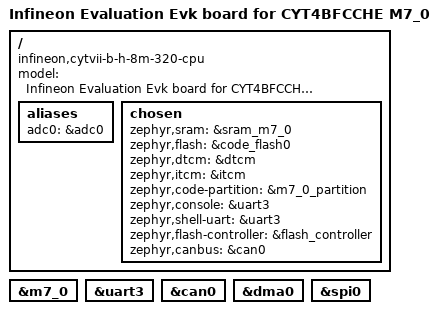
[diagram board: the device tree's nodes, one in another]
/*
 * Copyright (c) 2025 Infineon Technologies AG,
 * or an affiliate of Infineon Technologies AG.
 *
 * SPDX-License-Identifier: Apache-2.0
 */

/dts-v1/;
#include <arm/infineon/cat1c/traveo2-8m/cyt4bfcche.dtsi>
#include <arm/infineon/cat1c/traveo2-8m/system_clocks.dtsi>
#include <arm/infineon/cat1c/traveo2-8m/cyt4bf_m7.dtsi>
#include "cytvii_b_h_8m_320_cpu_common.dtsi"
#include "cytvii_b_h_8m_320_cpu_cyt4bfcche_m0p_pinctrl.dtsi"
#include <common/freq.h>

/ {
	model = "Infineon Evaluation Evk board for CYT4BFCCHE M7_0";
	compatible = "infineon,cytvii-b-h-8m-320-cpu", "infineon,CYTVIIBH8M";

	aliases {
		adc0 = &adc0;
	};

	chosen {
		zephyr,sram = &sram_m7_0;
		zephyr,flash = &code_flash0;
		zephyr,dtcm = &dtcm;
		zephyr,itcm = &itcm;
		zephyr,code-partition = &m7_0_partition;
		zephyr,console = &uart3;
		zephyr,shell-uart = &uart3;
		zephyr,flash-controller = &flash_controller;
		zephyr,canbus = &can0;
	};
};

&m7_0 {
	status = "okay";
};

&uart3 {
	status = "okay";
};

&can0 {
	status = "okay";
};

&dma0 {
	status = "okay";
};

&spi0 {
	status = "okay";
};
